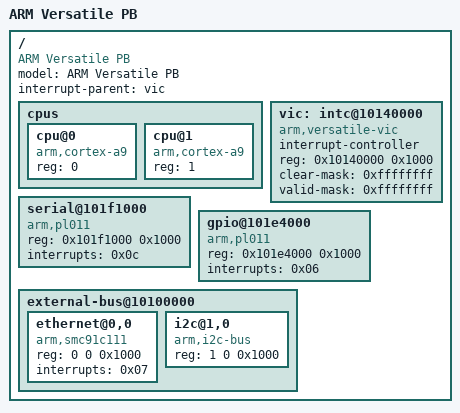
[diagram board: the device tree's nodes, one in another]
// SPDX-License-Identifier: GPL-2.0
/*
 * Update: 2020/7/2
 * Yutaka Hirata
 */
/dts-v1/;

/ {
	/* Device Treeの名前 */
	model = "ARM Versatile PB";

	/* デバイスドライバと紐付けする文字列 */
	compatible = "ARM Versatile PB";

	#address-cells = <1>;
	#size-cells = <1>;

	/* 割り込みコントローラー */
	interrupt-parent = <&vic>;

	/* プロセッサ */
	cpus {
		#address-cells = <1>;
		#size-cells = <0>;

		cpu@0 {
			compatible = "arm,cortex-a9";
			reg = <0>;
		};
		cpu@1 {
			compatible = "arm,cortex-a9";
			reg = <1>;
		};
	};

	/* 割り込みコントローラー */
	vic: intc@10140000 {
		compatible = "arm,versatile-vic";
		interrupt-controller;
		#interrupt-cells = <1>;
		reg = <0x10140000 0x1000>;
		clear-mask = <0xffffffff>;
		valid-mask = <0xffffffff>;
	};

	/* シリアルポートデバイス */
	serial@101f1000 {
		compatible = "arm,pl011";
		reg = < 0x101f1000 0x1000 >;
		interrupts = < 0x0c >;
	};

	/* GPIOデバイス */
	gpio@101e4000 {
		compatible = "arm,pl011";
		reg = < 0x101e4000 0x1000 >;
		interrupts = < 0x06 >;
	};

	/* 外部バス */
	external-bus@10100000 {
		#address-cells = <2>;
		#size-cells = <1>;

		ranges = <0 0 0x10100000   0x10000     // Chipselect 1, Ethernet
                  1 0 0x10160000   0x10000     // Chipselect 2, i2c controller
                 >;

		/* ネットワークデバイス */
		ethernet@0,0 {
			compatible = "arm,smc91c111";
			reg = < 0 0 0x1000 >;
			interrupts = < 0x07 >;
		};

		/* I2Cデバイス */
		i2c@1,0 {
			compatible = "arm,i2c-bus";
			reg = < 1 0 0x1000 >;
		};
	};
};

